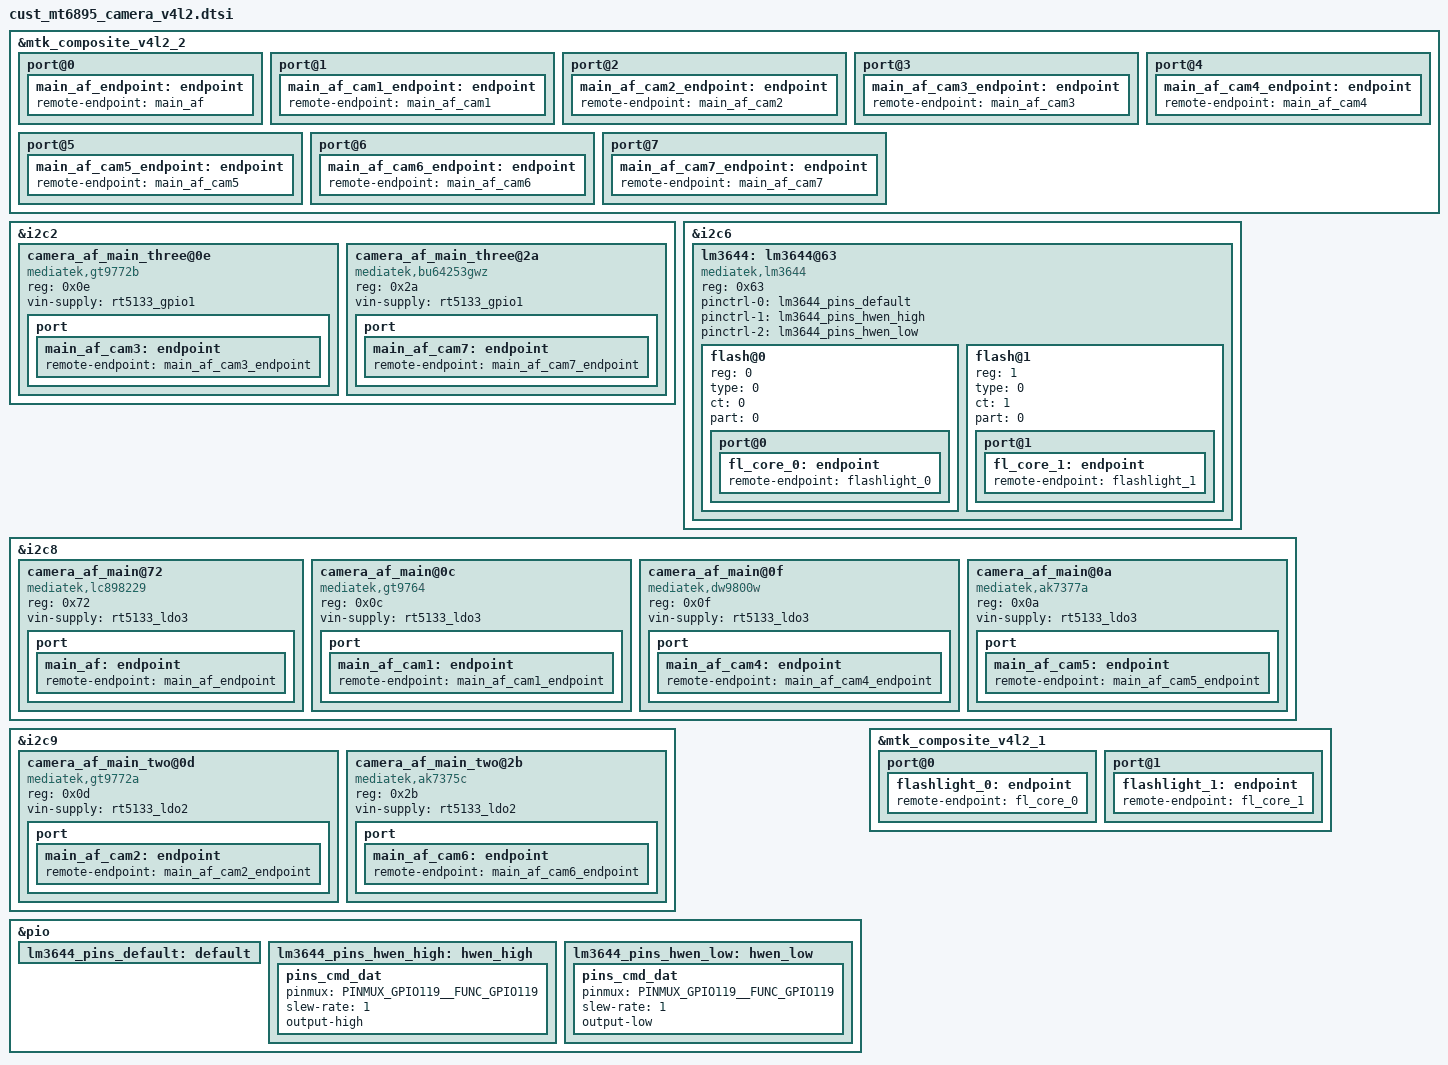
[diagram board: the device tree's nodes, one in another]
// SPDX-License-Identifier: GPL-2.0
/* Copyright (c) 2020 MediaTek Inc. */
&mtk_composite_v4l2_2 {
	port@0 {
		main_af_endpoint: endpoint {
			remote-endpoint = <&main_af>;
		};
	};
	port@1 {
		main_af_cam1_endpoint: endpoint {
			remote-endpoint = <&main_af_cam1>;
		};
	};
	port@2 {
		main_af_cam2_endpoint: endpoint {
			remote-endpoint = <&main_af_cam2>;
		};
	};
	port@3 {
		main_af_cam3_endpoint: endpoint {
			remote-endpoint = <&main_af_cam3>;
		};
	};
	port@4 {
		main_af_cam4_endpoint: endpoint {
			remote-endpoint = <&main_af_cam4>;
		};
	};
	port@5 {
		main_af_cam5_endpoint: endpoint {
			remote-endpoint = <&main_af_cam5>;
		};
	};
	port@6 {
		main_af_cam6_endpoint: endpoint {
			remote-endpoint = <&main_af_cam6>;
		};
	};
	port@7 {
		main_af_cam7_endpoint: endpoint {
			remote-endpoint = <&main_af_cam7>;
		};
	};
};

&i2c2 {
	camera_af_main_three@0e {
		compatible = "mediatek,gt9772b";
		reg = <0x0e>;
		vin-supply = <&rt5133_gpio1>;
		port {
			main_af_cam3: endpoint {
				remote-endpoint = <&main_af_cam3_endpoint>;
			};
		};
	};

	camera_af_main_three@2a {
		compatible = "mediatek,bu64253gwz";
		reg = <0x2a>;
		vin-supply = <&rt5133_gpio1>;
		port {
			main_af_cam7: endpoint {
				remote-endpoint = <&main_af_cam7_endpoint>;
			};
		};
	};
};

&i2c6 {
	lm3644:lm3644@63 {
		compatible = "mediatek,lm3644";
		reg = <0x63>;
		#cooling-cells = <2>;
		pinctrl-names = "default", "hwen_high", "hwen_low";
		pinctrl-0 = <&lm3644_pins_default>;
		pinctrl-1 = <&lm3644_pins_hwen_high>;
		pinctrl-2 = <&lm3644_pins_hwen_low>;
		status = "okay";
		flash@0{
			reg = <0>;
			type = <0>;
			ct = <0>;
			part = <0>;
			port@0 {
				fl_core_0: endpoint {
					remote-endpoint = <&flashlight_0>;
				};
			};
		};
		flash@1{
			reg = <1>;
			type = <0>;
			ct = <1>;
			part = <0>;
			port@1 {
				fl_core_1: endpoint {
					remote-endpoint = <&flashlight_1>;
				};
			};
		};
	};
};

&i2c8 {
	camera_af_main@72 {
		compatible = "mediatek,lc898229";
		reg = <0x72>;
		vin-supply = <&rt5133_ldo3>;
		port {
			main_af: endpoint {
				remote-endpoint = <&main_af_endpoint>;
			};
		};
	};

	camera_af_main@0c {
		compatible = "mediatek,gt9764";
		reg = <0x0c>;
		vin-supply = <&rt5133_ldo3>;
		port {
			main_af_cam1: endpoint {
				remote-endpoint = <&main_af_cam1_endpoint>;
			};
		};
	};

	camera_af_main@0f {
		compatible = "mediatek,dw9800w";
		reg = <0x0f>;
		vin-supply = <&rt5133_ldo3>;
		port {
			main_af_cam4: endpoint {
				remote-endpoint = <&main_af_cam4_endpoint>;
			};
		};
	};

	camera_af_main@0a {
		compatible = "mediatek,ak7377a";
		reg = <0x0a>;
		vin-supply = <&rt5133_ldo3>;
		port {
			main_af_cam5: endpoint {
				remote-endpoint = <&main_af_cam5_endpoint>;
			};
		};
	};
};

&i2c9 {
	camera_af_main_two@0d {
		compatible = "mediatek,gt9772a";
		reg = <0x0d>;
		vin-supply = <&rt5133_ldo2>;
		port {
			main_af_cam2: endpoint {
				remote-endpoint = <&main_af_cam2_endpoint>;
			};
		};
	};

	camera_af_main_two@2b {
		compatible = "mediatek,ak7375c";
		reg = <0x2b>;
		vin-supply = <&rt5133_ldo2>;
		port {
			main_af_cam6: endpoint {
				remote-endpoint = <&main_af_cam6_endpoint>;
			};
		};
	};
};

&pio {
	lm3644_pins_default: default {
	};

	lm3644_pins_hwen_high: hwen_high {
		pins_cmd_dat {
			pinmux = <PINMUX_GPIO119__FUNC_GPIO119>;
			slew-rate = <1>;
			output-high;
		};
	};

	lm3644_pins_hwen_low: hwen_low {
		pins_cmd_dat {
			pinmux = <PINMUX_GPIO119__FUNC_GPIO119>;
			slew-rate = <1>;
			output-low;
		};
	};
};

&mtk_composite_v4l2_1 {
	port@0 {
		flashlight_0: endpoint {
			remote-endpoint = <&fl_core_0>;
		};
	};
	port@1 {
		flashlight_1: endpoint {
			remote-endpoint = <&fl_core_1>;
		};
	};
};

